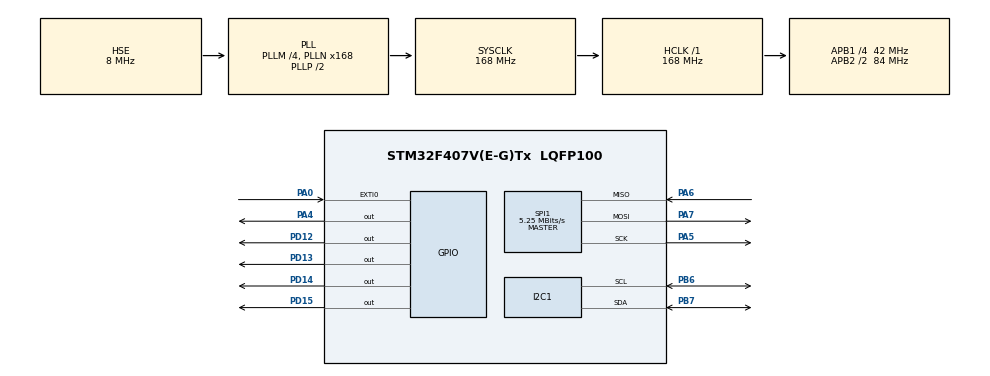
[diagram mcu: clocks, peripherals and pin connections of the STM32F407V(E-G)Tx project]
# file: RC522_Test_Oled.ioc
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I2C1.I2C_Mode=I2C_Fast
Mcu.Family=STM32F4
Mcu.Name=STM32F407V(E-G)Tx
Mcu.Package=LQFP100
NVIC.EXTI0_IRQn=true\:4\:0\:true\:false\:true
NVIC.I2C1_ER_IRQn=true\:1\:0\:true\:false\:true
NVIC.I2C1_EV_IRQn=true\:3\:0\:true\:false\:true
NVIC.PriorityGroup=NVIC_PRIORITYGROUP_4
NVIC.SPI1_IRQn=true\:2\:0\:true\:false\:true
PA0-WKUP.GPIO_PuPd=GPIO_NOPULL
PA0-WKUP.Signal=GPXTI0
PA4.GPIO_PuPd=GPIO_NOPULL
PA4.GPIO_Speed=GPIO_SPEED_FREQ_VERY_HIGH
PA4.PinState=GPIO_PIN_SET
PA4.Signal=GPIO_Output
PA5.Mode=Full_Duplex_Master
PA5.Signal=SPI1_SCK
PA6.Mode=Full_Duplex_Master
PA6.Signal=SPI1_MISO
PA7.Mode=Full_Duplex_Master
PA7.Signal=SPI1_MOSI
PB6.Mode=I2C
PB6.Signal=I2C1_SCL
PB7.Mode=I2C
PB7.Signal=I2C1_SDA
PD12.GPIO_PuPd=GPIO_NOPULL
PD12.GPIO_Speed=GPIO_SPEED_FREQ_VERY_HIGH
PD12.PinState=GPIO_PIN_RESET
PD12.Signal=GPIO_Output
PD13.GPIO_PuPd=GPIO_NOPULL
PD13.GPIO_Speed=GPIO_SPEED_FREQ_VERY_HIGH
PD13.PinState=GPIO_PIN_RESET
PD13.Signal=GPIO_Output
PD14.GPIO_PuPd=GPIO_NOPULL
PD14.GPIO_Speed=GPIO_SPEED_FREQ_VERY_HIGH
PD14.PinState=GPIO_PIN_RESET
PD14.Signal=GPIO_Output
PD15.GPIO_PuPd=GPIO_NOPULL
PD15.GPIO_Speed=GPIO_SPEED_FREQ_VERY_HIGH
PD15.PinState=GPIO_PIN_RESET
PD15.Signal=GPIO_Output
PH0-OSC_IN.Mode=HSE-External-Oscillator
PH0-OSC_IN.Signal=RCC_OSC_IN
PH1-OSC_OUT.Mode=HSE-External-Oscillator
PH1-OSC_OUT.Signal=RCC_OSC_OUT
ProjectManager.HeapSize=0x200
ProjectManager.StackSize=0x400
ProjectManager.TargetToolchain=MDK-ARM V5
RCC.48MHZClocksFreq_Value=84000000
RCC.AHBFreq_Value=168000000
RCC.APB1CLKDivider=RCC_HCLK_DIV4
RCC.APB1Freq_Value=42000000
RCC.APB1TimCLKDivider=1
RCC.APB1TimFreq_Value=42000000
RCC.APB2CLKDivider=RCC_HCLK_DIV2
RCC.APB2Freq_Value=84000000
RCC.APB2TimCLKDivider=1
RCC.APB2TimFreq_Value=84000000
RCC.CortexFreq_Value=168000000
RCC.HCLKFreq_Value=168000000
RCC.HSE_VALUE=8000000
RCC.HSI_VALUE=16000000
RCC.LSE_VALUE=32768
RCC.PLLM=4
RCC.PLLN=168
RCC.PLLSourceVirtual=RCC_PLLSOURCE_HSE
RCC.SYSCLKFreq_VALUE=168000000
RCC.SYSCLKSource=RCC_SYSCLKSOURCE_PLLCLK
RCC.VCOOutputFreq_Value=336000000
SPI1.BaudRatePrescaler=SPI_BAUDRATEPRESCALER_16
SPI1.CalculateBaudRate=5.25 MBits/s
SPI1.Mode=SPI_MODE_MASTER
board=RC522_Test_Oled

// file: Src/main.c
/*RC522      Stm32f407VG		Description
	NSS(SDA)       PA4        SP1_NSS control by software
	SCK            PA5
	MOSI					 PA7				SPI1_MOSI
	MISO					 PA6				SPI1_MISO
	RST            3V
	***********************************
	OLED0.96  Stm32f407VG
	SCL            PB6
	SDA						 PB7
	*/

#include "stm32f4xx_hal.h"
#include "rc522.h"
#include "ssd1306.h"
#include "fonts.h"
#include "stdio.h"

I2C_HandleTypeDef hi2c1;

SPI_HandleTypeDef hspi1;

/* USER CODE BEGIN PV */
/* Private variables ---------------------------------------------------------*/
uint8_t notice_true[]  = "Hop le";
uint8_t notice_false[] = "Khong hop le";
char buffer[5];
unsigned char card_id[5];
unsigned char my_card_id[5];
/* USER CODE END PV */

void SystemClock_Config(void);
static void MX_GPIO_Init(void);
static void MX_I2C1_Init(void);
static void MX_SPI1_Init(void);

/* USER CODE BEGIN PFP */

int main(void)
{
  /* Reset of all peripherals, Initializes the Flash interface and the Systick. */
  HAL_Init();

  /* Configure the system clock */
  SystemClock_Config();

  /* Initialize all configured peripherals */
  MX_GPIO_Init();
  MX_I2C1_Init();
  MX_SPI1_Init();
  MFRC522_Init();
  SSD1306_Init();

	spi1_enable();
	/*
	SSD1306_Fill(0);		//fill black screen
	SSD1306_GotoXY(0, 7);
	SSD1306_Puts("Waiting RFID Card", &Font_7x10, 1);
	//SSD1306_ScrollLeft(0, 7);
	SSD1306_UpdateScreen();
	HAL_Delay(2000);

	SSD1306_Clear();
	SSD1306_Fill(0);
	SSD1306_UpdateScreen();*/

  while (1)
  {
		if(MFRC522_Check(card_id) == MI_OK)
		{
			/*SSD1306_GotoXY(0, 15);
			sprintf(buffer, "%02x-%02x-%02x-%02x-%02x", card_id[0],card_id[1],card_id[2],card_id[3],card_id[4]);
		  SSD1306_Puts(buffer, &Font_7x10, 1);
			SD1306_Puts("done", &Font_7x10, 1);
			SSD1306_UpdateScreen();*/
			HAL_GPIO_WritePin(GPIOD, GPIO_PIN_12|GPIO_PIN_13|GPIO_PIN_14|GPIO_PIN_15, GPIO_PIN_SET);
			HAL_Delay(1000);
			HAL_GPIO_WritePin(GPIOD, GPIO_PIN_12|GPIO_PIN_13|GPIO_PIN_14|GPIO_PIN_15, GPIO_PIN_RESET);
		}
		HAL_Delay(10);

  }
  /* USER CODE END 3 */

}

/** System Clock Configuration
*/
void SystemClock_Config(void)
{

  RCC_OscInitTypeDef RCC_OscInitStruct;
  RCC_ClkInitTypeDef RCC_ClkInitStruct;

  __HAL_RCC_PWR_CLK_ENABLE();

  __HAL_PWR_VOLTAGESCALING_CONFIG(PWR_REGULATOR_VOLTAGE_SCALE1);

  RCC_OscInitStruct.OscillatorType = RCC_OSCILLATORTYPE_HSE;
  RCC_OscInitStruct.HSEState = RCC_HSE_ON;
  RCC_OscInitStruct.PLL.PLLState = RCC_PLL_ON;
  RCC_OscInitStruct.PLL.PLLSource = RCC_PLLSOURCE_HSE;
  RCC_OscInitStruct.PLL.PLLM = 4;
  RCC_OscInitStruct.PLL.PLLN = 168;
  RCC_OscInitStruct.PLL.PLLP = RCC_PLLP_DIV2;
  RCC_OscInitStruct.PLL.PLLQ = 4;
  HAL_RCC_OscConfig(&RCC_OscInitStruct);

  RCC_ClkInitStruct.ClockType = RCC_CLOCKTYPE_HCLK|RCC_CLOCKTYPE_SYSCLK
                              |RCC_CLOCKTYPE_PCLK1|RCC_CLOCKTYPE_PCLK2;
  RCC_ClkInitStruct.SYSCLKSource = RCC_SYSCLKSOURCE_PLLCLK;
  RCC_ClkInitStruct.AHBCLKDivider = RCC_SYSCLK_DIV1;
  RCC_ClkInitStruct.APB1CLKDivider = RCC_HCLK_DIV4;
  RCC_ClkInitStruct.APB2CLKDivider = RCC_HCLK_DIV2;
  HAL_RCC_ClockConfig(&RCC_ClkInitStruct, FLASH_LATENCY_5);

  HAL_SYSTICK_Config(HAL_RCC_GetHCLKFreq()/1000);

  HAL_SYSTICK_CLKSourceConfig(SYSTICK_CLKSOURCE_HCLK);

  /* SysTick_IRQn interrupt configuration */
  HAL_NVIC_SetPriority(SysTick_IRQn, 0, 0);
}

/* I2C1 init function */
void MX_I2C1_Init(void)
{

  hi2c1.Instance = I2C1;
  hi2c1.Init.ClockSpeed = 400000;
  hi2c1.Init.DutyCycle = I2C_DUTYCYCLE_2;
  hi2c1.Init.OwnAddress1 = 0;
  hi2c1.Init.AddressingMode = I2C_ADDRESSINGMODE_7BIT;
  hi2c1.Init.DualAddressMode = I2C_DUALADDRESS_DISABLE;
  hi2c1.Init.OwnAddress2 = 0;
  hi2c1.Init.GeneralCallMode = I2C_GENERALCALL_DISABLE;
  hi2c1.Init.NoStretchMode = I2C_NOSTRETCH_DISABLE;
  HAL_I2C_Init(&hi2c1);

}

/* SPI1 init function */
void MX_SPI1_Init(void)
{

  hspi1.Instance = SPI1;
  hspi1.Init.Mode = SPI_MODE_MASTER;
  hspi1.Init.Direction = SPI_DIRECTION_2LINES;
  hspi1.Init.DataSize = SPI_DATASIZE_8BIT;
  hspi1.Init.CLKPolarity = SPI_POLARITY_LOW;
  hspi1.Init.CLKPhase = SPI_PHASE_1EDGE;
  hspi1.Init.NSS = SPI_NSS_SOFT;
  hspi1.Init.BaudRatePrescaler = SPI_BAUDRATEPRESCALER_16;
  hspi1.Init.FirstBit = SPI_FIRSTBIT_MSB;
  hspi1.Init.TIMode = SPI_TIMODE_DISABLE;
  hspi1.Init.CRCCalculation = SPI_CRCCALCULATION_DISABLE;
  hspi1.Init.CRCPolynomial = 10;
  HAL_SPI_Init(&hspi1);

}

/** Configure pins as
        * Analog
        * Input
        * Output
        * EVENT_OUT
        * EXTI
*/
void MX_GPIO_Init(void)
{

  GPIO_InitTypeDef GPIO_InitStruct;

  /* GPIO Ports Clock Enable */
  __HAL_RCC_GPIOH_CLK_ENABLE();
  __HAL_RCC_GPIOA_CLK_ENABLE();
  __HAL_RCC_GPIOD_CLK_ENABLE();
  __HAL_RCC_GPIOB_CLK_ENABLE();

  /*Configure GPIO pin : PA0 */
  GPIO_InitStruct.Pin = GPIO_PIN_0;
  GPIO_InitStruct.Mode = GPIO_MODE_IT_RISING;
  GPIO_InitStruct.Pull = GPIO_NOPULL;
  HAL_GPIO_Init(GPIOA, &GPIO_InitStruct);

  /*Configure GPIO pin : PA4 */
  GPIO_InitStruct.Pin = GPIO_PIN_4;
  GPIO_InitStruct.Mode = GPIO_MODE_OUTPUT_PP;
  GPIO_InitStruct.Pull = GPIO_NOPULL;
  GPIO_InitStruct.Speed = GPIO_SPEED_FREQ_VERY_HIGH;
  HAL_GPIO_Init(GPIOA, &GPIO_InitStruct);

  /*Configure GPIO pins : PD12 PD13 PD14 PD15 */
  GPIO_InitStruct.Pin = GPIO_PIN_12|GPIO_PIN_13|GPIO_PIN_14|GPIO_PIN_15;
  GPIO_InitStruct.Mode = GPIO_MODE_OUTPUT_PP;
  GPIO_InitStruct.Pull = GPIO_NOPULL;
  GPIO_InitStruct.Speed = GPIO_SPEED_FREQ_VERY_HIGH;
  HAL_GPIO_Init(GPIOD, &GPIO_InitStruct);

  /*Configure GPIO pin Output Level */
  HAL_GPIO_WritePin(GPIOA, GPIO_PIN_4, GPIO_PIN_SET);

  /*Configure GPIO pin Output Level */
  HAL_GPIO_WritePin(GPIOD, GPIO_PIN_12|GPIO_PIN_13|GPIO_PIN_14|GPIO_PIN_15, GPIO_PIN_RESET);

  /* EXTI interrupt init*/
  HAL_NVIC_SetPriority(EXTI0_IRQn, 4, 0);
  HAL_NVIC_EnableIRQ(EXTI0_IRQn);

}

/************************ (C) COPYRIGHT STMicroelectronics *****END OF FILE****/
